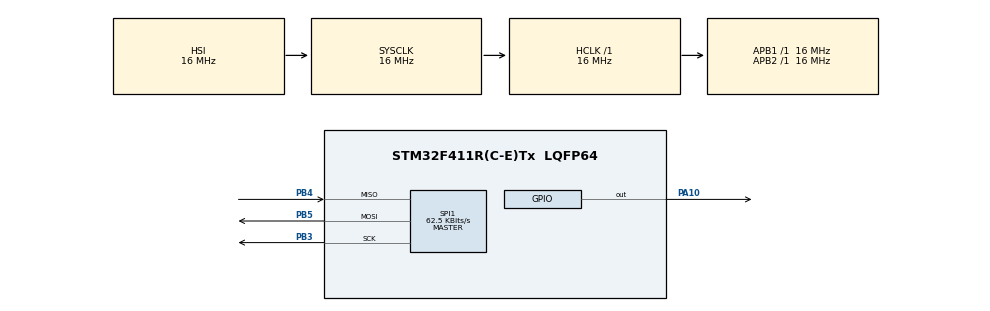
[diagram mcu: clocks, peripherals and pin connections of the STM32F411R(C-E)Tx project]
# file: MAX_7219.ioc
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Mcu.Family=STM32F4
Mcu.Name=STM32F411R(C-E)Tx
Mcu.Package=LQFP64
NVIC.PriorityGroup=NVIC_PRIORITYGROUP_4
PA10.Signal=GPIO_Output
PB3.Mode=Full_Duplex_Master
PB3.Signal=SPI1_SCK
PB4.Mode=Full_Duplex_Master
PB4.Signal=SPI1_MISO
PB5.Mode=Full_Duplex_Master
PB5.Signal=SPI1_MOSI
ProjectManager.HeapSize=0x200
ProjectManager.StackSize=0x400
ProjectManager.TargetToolchain=STM32CubeIDE
RCC.AHBFreq_Value=16000000
RCC.APB1Freq_Value=16000000
RCC.APB1TimFreq_Value=16000000
RCC.APB2Freq_Value=16000000
RCC.APB2TimFreq_Value=16000000
RCC.CortexFreq_Value=16000000
RCC.HCLKFreq_Value=16000000
RCC.HSE_VALUE=25000000
RCC.HSI_VALUE=16000000
RCC.LSE_VALUE=32768
RCC.SYSCLKFreq_VALUE=16000000
RCC.VCOOutputFreq_Value=192000000
SPI1.BaudRatePrescaler=SPI_BAUDRATEPRESCALER_256
SPI1.CalculateBaudRate=62.5 KBits/s
SPI1.Direction=SPI_DIRECTION_2LINES
SPI1.Mode=SPI_MODE_MASTER
SPI1.VirtualType=VM_MASTER
board=custom

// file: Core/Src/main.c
/* USER CODE BEGIN Header */
/**
  ******************************************************************************
  * @file           : main.c
  * @brief          : Main program body
  ******************************************************************************
  * @attention
  *
  * Copyright (c) 2022 STMicroelectronics.
  * All rights reserved.
  *
  * This software is licensed under terms that can be found in the LICENSE file
  * in the root directory of this software component.
  * If no LICENSE file comes with this software, it is provided AS-IS.
  *
  ******************************************************************************
  */
/* USER CODE END Header */
#include "main.h"

/* USER CODE BEGIN PTD */
uint8_t Tx_Buffer[4];
SPI_HandleTypeDef hspi1;
/* USER CODE END PTD */

/* USER CODE BEGIN PM */
void write_to_MAX7219(unsigned char register_addr, unsigned char data)
{
	HAL_GPIO_WritePin(GPIOA, GPIO_PIN_10, GPIO_PIN_RESET);
//	HAL_Delay(2);
	Tx_Buffer[0] = register_addr;
	Tx_Buffer[1] = data;
	HAL_SPI_Transmit(&hspi1, Tx_Buffer, 2, 10);
	HAL_GPIO_WritePin(GPIOA, GPIO_PIN_10, GPIO_PIN_SET);
}
/* USER CODE END PM */

void SystemClock_Config(void);
static void MX_GPIO_Init(void);
static void MX_SPI1_Init(void);

int main(void)
{

  /* MCU Configuration--------------------------------------------------------*/

  /* Reset of all peripherals, Initializes the Flash interface and the Systick. */
  HAL_Init();

  /* Configure the system clock */
  SystemClock_Config();

  /* Initialize all configured peripherals */
  MX_GPIO_Init();
  MX_SPI1_Init();
  /* USER CODE BEGIN 2 */

  write_to_MAX7219(0x0c, 0x01);        //(Shut Down Mode, Normal Mode)
  write_to_MAX7219(0x09, 0x00);        //()
  write_to_MAX7219(0x0A, 0x01);
  write_to_MAX7219(0x0B, 0x07);

  /* USER CODE END 2 */

  /* Infinite loop */
  while (1)
  {
	  write_to_MAX7219(0x01, 0x01);
	  write_to_MAX7219(0x02, 0x00);
	  write_to_MAX7219(0x03, 0x00);
	  write_to_MAX7219(0x04, 0x24);
	  write_to_MAX7219(0x05, 0x3E);
	  write_to_MAX7219(0x06, 0x20);
	  write_to_MAX7219(0x07, 0x00);
	  write_to_MAX7219(0x08, 0x00);
	  HAL_Delay(1000);
	  write_to_MAX7219(0x01, 0x01);
	  write_to_MAX7219(0x02, 0x00);
	  write_to_MAX7219(0x03, 0x00);
	  write_to_MAX7219(0x04, 0x3A);
	  write_to_MAX7219(0x05, 0x2A);
	  write_to_MAX7219(0x06, 0x2E);
	  write_to_MAX7219(0x07, 0x00);
	  write_to_MAX7219(0x08, 0x00);
	  HAL_Delay(1000);
	  write_to_MAX7219(0x01, 0x01);
	  write_to_MAX7219(0x02, 0x00);
	  write_to_MAX7219(0x03, 0x00);
	  write_to_MAX7219(0x04, 0x2A);
	  write_to_MAX7219(0x05, 0x2A);
	  write_to_MAX7219(0x06, 0x3E);
	  write_to_MAX7219(0x07, 0x00);
	  write_to_MAX7219(0x08, 0x00);
	  HAL_Delay(1000);
	  write_to_MAX7219(0x01, 0x01);
	  write_to_MAX7219(0x02, 0x00);
	  write_to_MAX7219(0x03, 0x00);
	  write_to_MAX7219(0x04, 0x0E);
	  write_to_MAX7219(0x05, 0x08);
	  write_to_MAX7219(0x06, 0x3E);
	  write_to_MAX7219(0x07, 0x00);
	  write_to_MAX7219(0x08, 0x00);
	  HAL_Delay(1000);
	  write_to_MAX7219(0x01, 0x01);
	  write_to_MAX7219(0x02, 0x00);
	  write_to_MAX7219(0x03, 0x00);
	  write_to_MAX7219(0x04, 0x2E);
	  write_to_MAX7219(0x05, 0x2A);
	  write_to_MAX7219(0x06, 0x3A);
	  write_to_MAX7219(0x07, 0x00);
	  write_to_MAX7219(0x08, 0x00);
	  HAL_Delay(1000);
	  write_to_MAX7219(0x01, 0x01);
	  write_to_MAX7219(0x02, 0x00);
	  write_to_MAX7219(0x03, 0x00);
	  write_to_MAX7219(0x04, 0x3E);
	  write_to_MAX7219(0x05, 0x2A);
	  write_to_MAX7219(0x06, 0x3A);
	  write_to_MAX7219(0x07, 0x00);
	  write_to_MAX7219(0x08, 0x00);
	  HAL_Delay(1000);
	  write_to_MAX7219(0x01, 0x01);
	  write_to_MAX7219(0x02, 0x00);
	  write_to_MAX7219(0x03, 0x00);
	  write_to_MAX7219(0x04, 0x02);
	  write_to_MAX7219(0x05, 0x0A);
	  write_to_MAX7219(0x06, 0x3E);
	  write_to_MAX7219(0x07, 0x08);
	  write_to_MAX7219(0x08, 0x00);
	  HAL_Delay(1000);
	  write_to_MAX7219(0x01, 0x01);
	  write_to_MAX7219(0x02, 0x00);
	  write_to_MAX7219(0x03, 0x00);
	  write_to_MAX7219(0x04, 0x3E);
	  write_to_MAX7219(0x05, 0x2A);
	  write_to_MAX7219(0x06, 0x3E);
	  write_to_MAX7219(0x07, 0x00);
	  write_to_MAX7219(0x08, 0x00);
	  HAL_Delay(1000);
	  write_to_MAX7219(0x01, 0x01);
	  write_to_MAX7219(0x02, 0x00);
	  write_to_MAX7219(0x03, 0x00);
	  write_to_MAX7219(0x04, 0x2E);
	  write_to_MAX7219(0x05, 0x2A);
	  write_to_MAX7219(0x06, 0x3E);
	  write_to_MAX7219(0x07, 0x00);
	  write_to_MAX7219(0x08, 0x00);
	  HAL_Delay(1000);
	  write_to_MAX7219(0x01, 0x24);
	  write_to_MAX7219(0x02, 0x3E);
	  write_to_MAX7219(0x03, 0x20);
	  write_to_MAX7219(0x04, 0x00);
	  write_to_MAX7219(0x05, 0x3E);
	  write_to_MAX7219(0x06, 0x22);
	  write_to_MAX7219(0x07, 0x3E);
	  write_to_MAX7219(0x08, 0x00);
	  HAL_Delay(1000);
	  write_to_MAX7219(0x01, 0x0E);
	  write_to_MAX7219(0x02, 0x1F);
	  write_to_MAX7219(0x03, 0x3F);
	  write_to_MAX7219(0x04, 0x7E);
	  write_to_MAX7219(0x05, 0x7E);
	  write_to_MAX7219(0x06, 0x3F);
	  write_to_MAX7219(0x07, 0x1F);
	  write_to_MAX7219(0x08, 0x0E);
	  HAL_Delay(1000);

  }
}

void SystemClock_Config(void)
{
  RCC_OscInitTypeDef RCC_OscInitStruct = {0};
  RCC_ClkInitTypeDef RCC_ClkInitStruct = {0};

  /** Configure the main internal regulator output voltage
  */
  __HAL_RCC_PWR_CLK_ENABLE();
  __HAL_PWR_VOLTAGESCALING_CONFIG(PWR_REGULATOR_VOLTAGE_SCALE1);

  /** Initializes the RCC Oscillators according to the specified parameters
  * in the RCC_OscInitTypeDef structure.
  */
  RCC_OscInitStruct.OscillatorType = RCC_OSCILLATORTYPE_HSI;
  RCC_OscInitStruct.HSIState = RCC_HSI_ON;
  RCC_OscInitStruct.HSICalibrationValue = RCC_HSICALIBRATION_DEFAULT;
  RCC_OscInitStruct.PLL.PLLState = RCC_PLL_NONE;
  if (HAL_RCC_OscConfig(&RCC_OscInitStruct) != HAL_OK)
  {
    Error_Handler();
  }

  /** Initializes the CPU, AHB and APB buses clocks
  */
  RCC_ClkInitStruct.ClockType = RCC_CLOCKTYPE_HCLK|RCC_CLOCKTYPE_SYSCLK
                              |RCC_CLOCKTYPE_PCLK1|RCC_CLOCKTYPE_PCLK2;
  RCC_ClkInitStruct.SYSCLKSource = RCC_SYSCLKSOURCE_HSI;
  RCC_ClkInitStruct.AHBCLKDivider = RCC_SYSCLK_DIV1;
  RCC_ClkInitStruct.APB1CLKDivider = RCC_HCLK_DIV1;
  RCC_ClkInitStruct.APB2CLKDivider = RCC_HCLK_DIV1;

  if (HAL_RCC_ClockConfig(&RCC_ClkInitStruct, FLASH_LATENCY_0) != HAL_OK)
  {
    Error_Handler();
  }
}

static void MX_SPI1_Init(void)
{

  /* SPI1 parameter configuration*/
  hspi1.Instance = SPI1;
  hspi1.Init.Mode = SPI_MODE_MASTER;
  hspi1.Init.Direction = SPI_DIRECTION_2LINES;
  hspi1.Init.DataSize = SPI_DATASIZE_8BIT;
  hspi1.Init.CLKPolarity = SPI_POLARITY_LOW;
  hspi1.Init.CLKPhase = SPI_PHASE_1EDGE;
  hspi1.Init.NSS = SPI_NSS_SOFT;
  hspi1.Init.BaudRatePrescaler = SPI_BAUDRATEPRESCALER_256;
  hspi1.Init.FirstBit = SPI_FIRSTBIT_MSB;
  hspi1.Init.TIMode = SPI_TIMODE_DISABLE;
  hspi1.Init.CRCCalculation = SPI_CRCCALCULATION_DISABLE;
  hspi1.Init.CRCPolynomial = 10;
  if (HAL_SPI_Init(&hspi1) != HAL_OK)
  {
    Error_Handler();
  }

}

static void MX_GPIO_Init(void)
{
  GPIO_InitTypeDef GPIO_InitStruct = {0};

  /* GPIO Ports Clock Enable */
  __HAL_RCC_GPIOA_CLK_ENABLE();
  __HAL_RCC_GPIOB_CLK_ENABLE();

  /*Configure GPIO pin Output Level */
  HAL_GPIO_WritePin(GPIOA, GPIO_PIN_10, GPIO_PIN_RESET);

  /*Configure GPIO pin : PA10 */
  GPIO_InitStruct.Pin = GPIO_PIN_10;
  GPIO_InitStruct.Mode = GPIO_MODE_OUTPUT_PP;
  GPIO_InitStruct.Pull = GPIO_NOPULL;
  GPIO_InitStruct.Speed = GPIO_SPEED_FREQ_LOW;
  HAL_GPIO_Init(GPIOA, &GPIO_InitStruct);

}

void Error_Handler(void)
{
  __disable_irq();
  while (1)
  {
  }
}
